AUTOSAR XML (schema 4-2-2)
package /STELLANTIS/EPT/ASWCs
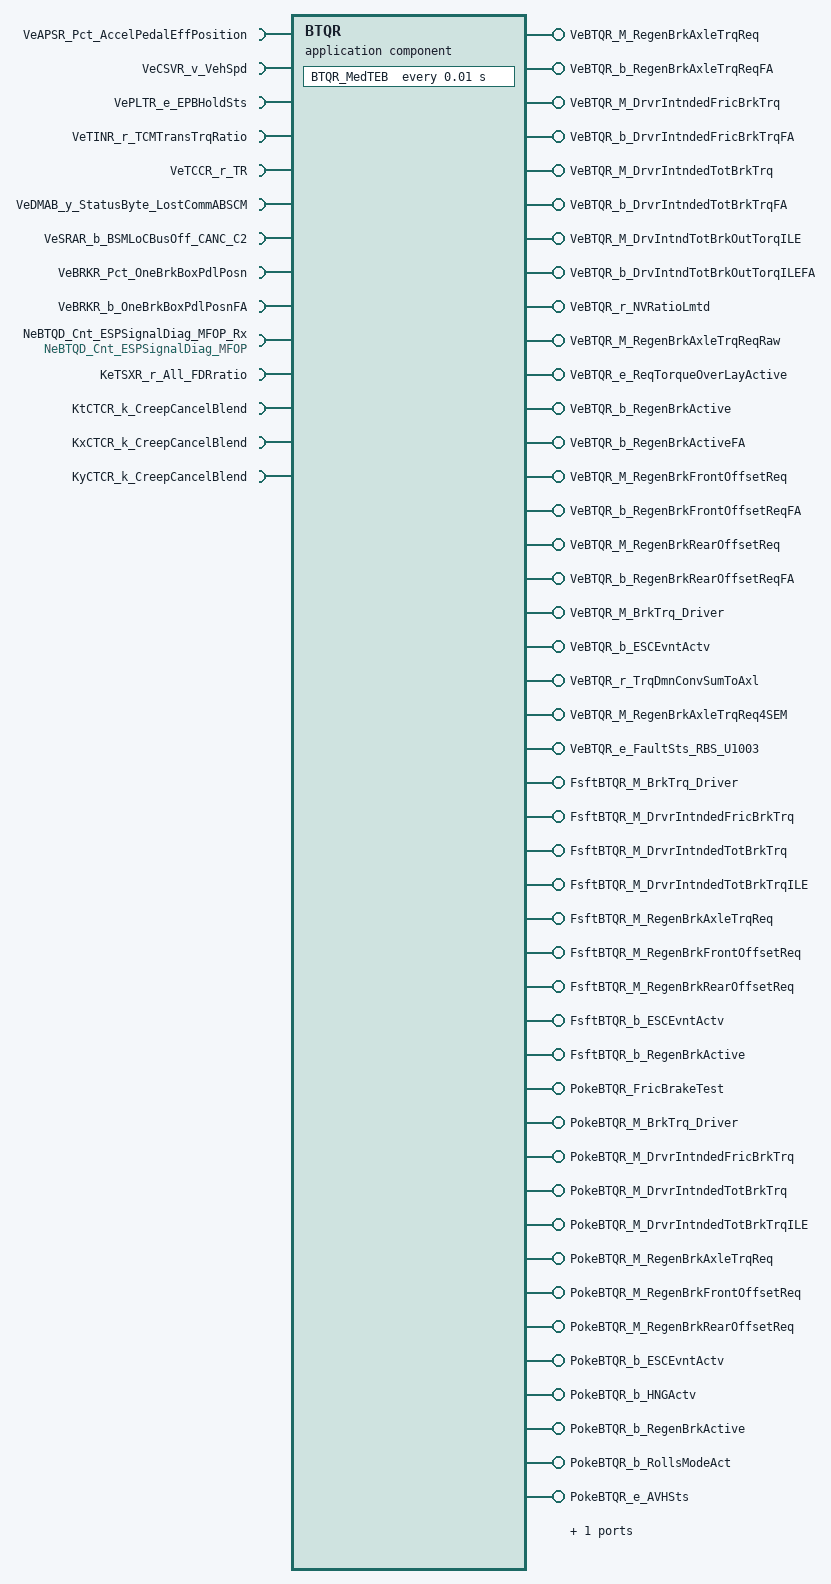
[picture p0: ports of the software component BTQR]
  application sw component type BTQR
    9 x require port:
      VeAPSR_Pct_AccelPedalEffPosition: variation-point={short-label=vpVeAPSR_Pct_AccelPedalEffPosition, sw-syscond=1}, nonqueued-receiver-com-spec{data-element=Value, init-value=0}, required-interface=VeAPSR_Pct_AccelPedalEffPosition
      VeCSVR_v_VehSpd: nonqueued-receiver-com-spec{data-element=Value, init-value=0}, required-interface=VeCSVR_v_VehSpd
      VePLTR_e_EPBHoldSts: variation-point={short-label=vpVePLTR_e_EPBHoldSts, sw-syscond=1}, nonqueued-receiver-com-spec{data-element=Value, init-value=CePLTR_e_EPBHoldSts_REL}, required-interface=VePLTR_e_EPBHoldSts
      VeTINR_r_TCMTransTrqRatio: variation-point={short-label=vpVeTINR_r_TCMTransTrqRatio, sw-syscond=1}, nonqueued-receiver-com-spec{data-element=Value, init-value=0}, required-interface=VeTINR_r_TCMTransTrqRatio
      VeTCCR_r_TR: variation-point={short-label=vpVeTCCR_r_TR, sw-syscond=1}, nonqueued-receiver-com-spec{data-element=Value, init-value=0}, required-interface=VeTCCR_r_TR
      VeDMAB_y_StatusByte_LostCommABSCM: nonqueued-receiver-com-spec{data-element=Value, init-value=0}, required-interface=VeDMAB_y_StatusByte_LostCommABSCM
      VeSRAR_b_BSMLoCBusOff_CANC_C2: variation-point={short-label=vpVeSRAR_b_BSMLoCBusOff_CANC_C2, sw-syscond=1}, nonqueued-receiver-com-spec{data-element=Value, init-value=0}, required-interface=VeSRAR_b_BSMLoCBusOff_CANC_C2
      VeBRKR_Pct_OneBrkBoxPdlPosn: variation-point={short-label=vpVeBRKR_Pct_OneBrkBoxPdlPosn, sw-syscond=1}, nonqueued-receiver-com-spec{data-element=Value, init-value=0}, required-interface=VeBRKR_Pct_OneBrkBoxPdlPosn
      VeBRKR_b_OneBrkBoxPdlPosnFA: variation-point={short-label=vpVeBRKR_b_OneBrkBoxPdlPosnFA, sw-syscond=1}, nonqueued-receiver-com-spec{data-element=Value, init-value=0}, required-interface=VeBRKR_b_OneBrkBoxPdlPosnFA
    44 x provide port:
      VeBTQR_M_RegenBrkAxleTrqReq: nonqueued-sender-com-spec{data-element=Value, init-value=0}, provided-interface=VeBTQR_M_RegenBrkAxleTrqReq
      VeBTQR_b_RegenBrkAxleTrqReqFA: nonqueued-sender-com-spec{data-element=Value, init-value=0}, provided-interface=VeBTQR_b_RegenBrkAxleTrqReqFA
      VeBTQR_M_DrvrIntndedFricBrkTrq: nonqueued-sender-com-spec{data-element=Value, init-value=0}, provided-interface=VeBTQR_M_DrvrIntndedFricBrkTrq
      VeBTQR_b_DrvrIntndedFricBrkTrqFA: nonqueued-sender-com-spec{data-element=Value, init-value=0}, provided-interface=VeBTQR_b_DrvrIntndedFricBrkTrqFA
      VeBTQR_M_DrvrIntndedTotBrkTrq: nonqueued-sender-com-spec{data-element=Value, init-value=0}, provided-interface=VeBTQR_M_DrvrIntndedTotBrkTrq
      VeBTQR_b_DrvrIntndedTotBrkTrqFA: nonqueued-sender-com-spec{data-element=Value, init-value=0}, provided-interface=VeBTQR_b_DrvrIntndedTotBrkTrqFA
      VeBTQR_M_DrvIntndTotBrkOutTorqILE: nonqueued-sender-com-spec{data-element=Value, init-value=0}, provided-interface=VeBTQR_M_DrvIntndTotBrkOutTorqILE
      VeBTQR_b_DrvIntndTotBrkOutTorqILEFA: nonqueued-sender-com-spec{data-element=Value, init-value=0}, provided-interface=VeBTQR_b_DrvIntndTotBrkOutTorqILEFA
      VeBTQR_r_NVRatioLmtd: nonqueued-sender-com-spec{data-element=Value, init-value=0}, provided-interface=VeBTQR_r_NVRatioLmtd
      VeBTQR_M_RegenBrkAxleTrqReqRaw: nonqueued-sender-com-spec{data-element=Value, init-value=0}, provided-interface=VeBTQR_M_RegenBrkAxleTrqReqRaw
      VeBTQR_e_ReqTorqueOverLayActive: nonqueued-sender-com-spec{data-element=Value, init-value=CeBTQR_e_NotApplied}, provided-interface=VeBTQR_e_ReqTorqueOverLayActive
      VeBTQR_b_RegenBrkActive: nonqueued-sender-com-spec{data-element=Value, init-value=0}, provided-interface=VeBTQR_b_RegenBrkActive
      VeBTQR_b_RegenBrkActiveFA: nonqueued-sender-com-spec{data-element=Value, init-value=0}, provided-interface=VeBTQR_b_RegenBrkActiveFA
      VeBTQR_M_RegenBrkFrontOffsetReq: nonqueued-sender-com-spec{data-element=Value, init-value=0}, provided-interface=VeBTQR_M_RegenBrkFrontOffsetReq
      VeBTQR_b_RegenBrkFrontOffsetReqFA: nonqueued-sender-com-spec{data-element=Value, init-value=0}, provided-interface=VeBTQR_b_RegenBrkFrontOffsetReqFA
      VeBTQR_M_RegenBrkRearOffsetReq: nonqueued-sender-com-spec{data-element=Value, init-value=0}, provided-interface=VeBTQR_M_RegenBrkRearOffsetReq
      VeBTQR_b_RegenBrkRearOffsetReqFA: nonqueued-sender-com-spec{data-element=Value, init-value=0}, provided-interface=VeBTQR_b_RegenBrkRearOffsetReqFA
      VeBTQR_M_BrkTrq_Driver: variation-point={short-label=vpVeBTQR_M_BrkTrq_Driver, sw-syscond=1}, nonqueued-sender-com-spec{data-element=Value, init-value=0}, provided-interface=VeBTQR_M_BrkTrq_Driver
      VeBTQR_b_ESCEvntActv: nonqueued-sender-com-spec{data-element=Value, init-value=0}, provided-interface=VeBTQR_b_ESCEvntActv
      VeBTQR_r_TrqDmnConvSumToAxl: nonqueued-sender-com-spec{data-element=Value, init-value=0}, provided-interface=VeBTQR_r_TrqDmnConvSumToAxl
      VeBTQR_M_RegenBrkAxleTrqReq4SEM: nonqueued-sender-com-spec{data-element=Value, init-value=0}, provided-interface=VeBTQR_M_RegenBrkAxleTrqReq4SEM
      VeBTQR_e_FaultSts_RBS_U1003: nonqueued-sender-com-spec{data-element=Value, init-value=CeDFIB_e_Init}, provided-interface=VeBTQR_e_FaultSts_RBS_U1003
      FsftBTQR_M_BrkTrq_Driver: server-com-spec=FsftBTQR_M_BrkTrq_Driver, provided-interface=FsftBTQR_M_BrkTrq_Driver
      FsftBTQR_M_DrvrIntndedFricBrkTrq: server-com-spec=FsftBTQR_M_DrvrIntndedFricBrkTrq, provided-interface=FsftBTQR_M_DrvrIntndedFricBrkTrq
      FsftBTQR_M_DrvrIntndedTotBrkTrq: server-com-spec=FsftBTQR_M_DrvrIntndedTotBrkTrq, provided-interface=FsftBTQR_M_DrvrIntndedTotBrkTrq
      FsftBTQR_M_DrvrIntndedTotBrkTrqILE: server-com-spec=FsftBTQR_M_DrvrIntndedTotBrkTrqILE, provided-interface=FsftBTQR_M_DrvrIntndedTotBrkTrqILE
      FsftBTQR_M_RegenBrkAxleTrqReq: server-com-spec=FsftBTQR_M_RegenBrkAxleTrqReq, provided-interface=FsftBTQR_M_RegenBrkAxleTrqReq
      FsftBTQR_M_RegenBrkFrontOffsetReq: server-com-spec=FsftBTQR_M_RegenBrkFrontOffsetReq, provided-interface=FsftBTQR_M_RegenBrkFrontOffsetReq
      FsftBTQR_M_RegenBrkRearOffsetReq: server-com-spec=FsftBTQR_M_RegenBrkRearOffsetReq, provided-interface=FsftBTQR_M_RegenBrkRearOffsetReq
      FsftBTQR_b_ESCEvntActv: server-com-spec=FsftBTQR_b_ESCEvntActv, provided-interface=FsftBTQR_b_ESCEvntActv
      FsftBTQR_b_RegenBrkActive: server-com-spec=FsftBTQR_b_RegenBrkActive, provided-interface=FsftBTQR_b_RegenBrkActive
      PokeBTQR_FricBrakeTest: server-com-spec{operation=PokeBTQR_FricBrakeTest, queue-length=1}, provided-interface=PokeBTQR_FricBrakeTest
      PokeBTQR_M_BrkTrq_Driver: server-com-spec{operation=PokeBTQR_M_BrkTrq_Driver, queue-length=1}, provided-interface=PokeBTQR_M_BrkTrq_Driver
      PokeBTQR_M_DrvrIntndedFricBrkTrq: server-com-spec{operation=PokeBTQR_M_DrvrIntndedFricBrkTrq, queue-length=1}, provided-interface=PokeBTQR_M_DrvrIntndedFricBrkTrq
      PokeBTQR_M_DrvrIntndedTotBrkTrq: server-com-spec{operation=PokeBTQR_M_DrvrIntndedTotBrkTrq, queue-length=1}, provided-interface=PokeBTQR_M_DrvrIntndedTotBrkTrq
      PokeBTQR_M_DrvrIntndedTotBrkTrqILE: server-com-spec{operation=PokeBTQR_M_DrvrIntndedTotBrkTrqILE, queue-length=1}, provided-interface=PokeBTQR_M_DrvrIntndedTotBrkTrqILE
      PokeBTQR_M_RegenBrkAxleTrqReq: server-com-spec{operation=PokeBTQR_M_RegenBrkAxleTrqReq, queue-length=1}, provided-interface=PokeBTQR_M_RegenBrkAxleTrqReq
      PokeBTQR_M_RegenBrkFrontOffsetReq: server-com-spec{operation=PokeBTQR_M_RegenBrkFrontOffsetReq, queue-length=1}, provided-interface=PokeBTQR_M_RegenBrkFrontOffsetReq
      PokeBTQR_M_RegenBrkRearOffsetReq: server-com-spec{operation=PokeBTQR_M_RegenBrkRearOffsetReq, queue-length=1}, provided-interface=PokeBTQR_M_RegenBrkRearOffsetReq
      PokeBTQR_b_ESCEvntActv: server-com-spec{operation=PokeBTQR_b_ESCEvntActv, queue-length=1}, provided-interface=PokeBTQR_b_ESCEvntActv
      PokeBTQR_b_HNGActv: server-com-spec{operation=PokeBTQR_b_HNGActv, queue-length=1}, provided-interface=PokeBTQR_b_HNGActv
      PokeBTQR_b_RegenBrkActive: server-com-spec{operation=PokeBTQR_b_RegenBrkActive, queue-length=1}, provided-interface=PokeBTQR_b_RegenBrkActive
      PokeBTQR_b_RollsModeAct: server-com-spec{operation=PokeBTQR_b_RollsModeAct, queue-length=1}, provided-interface=PokeBTQR_b_RollsModeAct
      PokeBTQR_e_AVHSts: server-com-spec{operation=PokeBTQR_e_AVHSts, queue-length=1}, provided-interface=PokeBTQR_e_AVHSts
    require port NeBTQD_Cnt_ESPSignalDiag_MFOP_Rx: nv-require-com-spec{init-value=0, variable=NeBTQD_Cnt_ESPSignalDiag_MFOP}, required-interface=NeBTQD_Cnt_ESPSignalDiag_MFOP
    provide port NeBTQD_Cnt_ESPSignalDiag_MFOP: nv-provide-com-spec{ram-block-init-value=0, variable=NeBTQD_Cnt_ESPSignalDiag_MFOP}, provided-interface=NeBTQD_Cnt_ESPSignalDiag_MFOP
    4 x require port:
      KeTSXR_r_All_FDRratio: parameter-require-com-spec{init-value=KeTSXR_r_All_FDRratio_KeTSXR_r_All_FDRratio:3.64023876190186, parameter=KeTSXR_r_All_FDRratio}, required-interface=KeTSXR_r_All_FDRratio
      KtCTCR_k_CreepCancelBlend: parameter-require-com-spec{init-value=[1 1 1 1 1 1 0.899999976158142 0.800000011920929 0.699999988079071 0.5 0.400000005960464 0.300000011920929 0.699999988079071 0.649999976158142 0.600000023841858 0.400000005960464 0.300000011920929 0.25 0.5 0.449999988079071 0.400000005960464 0.300000011920929 0.25 0.200000002980232 0.300000011920929 0.25 0.200000002980232 0.150000005960464 0.100000001490116 0.0500000007450581 0 0 0 0 0 0], parameter=KtCTCR_k_CreepCancelBlend}, required-interface=KtCTCR_k_CreepCancelBlend
      KxCTCR_k_CreepCancelBlend: parameter-require-com-spec{init-value=[0 2 5 7 10 20], parameter=KxCTCR_k_CreepCancelBlend}, required-interface=KxCTCR_k_CreepCancelBlend
      KyCTCR_k_CreepCancelBlend: parameter-require-com-spec{init-value=[0 200 500 1000 2000 2500], parameter=KyCTCR_k_CreepCancelBlend}, required-interface=KyCTCR_k_CreepCancelBlend
    behavior IB_BTQR: data-type-mapping=msADTtoIDTMapping, handle-termination-and-restart=NO-SUPPORT
      timing event Event_MedTEB: start-on-event=BTQR_MedTEB, period=0.01
      20 x operation invoked event:
        Event_FsftBTQR_M_BrkTrq_Driver: start-on-event=FsftBTQR_M_BrkTrq_Driver, operation=FsftBTQR_M_BrkTrq_Driver.FsftBTQR_M_BrkTrq_Driver
        Event_FsftBTQR_M_DrvrIntndedFricBrkTrq: start-on-event=FsftBTQR_M_DrvrIntndedFricBrkTrq, operation=FsftBTQR_M_DrvrIntndedFricBrkTrq.FsftBTQR_M_DrvrIntndedFricBrkTrq
        Event_FsftBTQR_M_DrvrIntndedTotBrkTrq: start-on-event=FsftBTQR_M_DrvrIntndedTotBrkTrq, operation=FsftBTQR_M_DrvrIntndedTotBrkTrq.FsftBTQR_M_DrvrIntndedTotBrkTrq
        Event_FsftBTQR_M_DrvrIntndedTotBrkTrqILE: start-on-event=FsftBTQR_M_DrvrIntndedTotBrkTrqILE, operation=FsftBTQR_M_DrvrIntndedTotBrkTrqILE.FsftBTQR_M_DrvrIntndedTotBrkTrqILE
        Event_FsftBTQR_M_RegenBrkAxleTrqReq: start-on-event=FsftBTQR_M_RegenBrkAxleTrqReq, operation=FsftBTQR_M_RegenBrkAxleTrqReq.FsftBTQR_M_RegenBrkAxleTrqReq
        Event_FsftBTQR_M_RegenBrkFrontOffsetReq: start-on-event=FsftBTQR_M_RegenBrkFrontOffsetReq, operation=FsftBTQR_M_RegenBrkFrontOffsetReq.FsftBTQR_M_RegenBrkFrontOffsetReq
        Event_FsftBTQR_M_RegenBrkRearOffsetReq: start-on-event=FsftBTQR_M_RegenBrkRearOffsetReq, operation=FsftBTQR_M_RegenBrkRearOffsetReq.FsftBTQR_M_RegenBrkRearOffsetReq
        Event_FsftBTQR_b_ESCEvntActv: start-on-event=FsftBTQR_b_ESCEvntActv, operation=FsftBTQR_b_ESCEvntActv.FsftBTQR_b_ESCEvntActv
        Event_FsftBTQR_b_RegenBrkActive: start-on-event=FsftBTQR_b_RegenBrkActive, operation=FsftBTQR_b_RegenBrkActive.FsftBTQR_b_RegenBrkActive
        Event_PokeBTQR_M_BrkTrq_Driver: start-on-event=PokeBTQR_M_BrkTrq_Driver, operation=PokeBTQR_M_BrkTrq_Driver.PokeBTQR_M_BrkTrq_Driver
        Event_PokeBTQR_M_DrvrIntndedFricBrkTrq: start-on-event=PokeBTQR_M_DrvrIntndedFricBrkTrq, operation=PokeBTQR_M_DrvrIntndedFricBrkTrq.PokeBTQR_M_DrvrIntndedFricBrkTrq
        Event_PokeBTQR_M_DrvrIntndedTotBrkTrq: start-on-event=PokeBTQR_M_DrvrIntndedTotBrkTrq, operation=PokeBTQR_M_DrvrIntndedTotBrkTrq.PokeBTQR_M_DrvrIntndedTotBrkTrq
        Event_PokeBTQR_M_DrvrIntndedTotBrkTrqILE: start-on-event=PokeBTQR_M_DrvrIntndedTotBrkTrqILE, operation=PokeBTQR_M_DrvrIntndedTotBrkTrqILE.PokeBTQR_M_DrvrIntndedTotBrkTrqILE
        Event_PokeBTQR_M_RegenBrkAxleTrqReq: start-on-event=PokeBTQR_M_RegenBrkAxleTrqReq, operation=PokeBTQR_M_RegenBrkAxleTrqReq.PokeBTQR_M_RegenBrkAxleTrqReq
        Event_PokeBTQR_M_RegenBrkFrontOffsetReq: start-on-event=PokeBTQR_M_RegenBrkFrontOffsetReq, operation=PokeBTQR_M_RegenBrkFrontOffsetReq.PokeBTQR_M_RegenBrkFrontOffsetReq
        Event_PokeBTQR_M_RegenBrkRearOffsetReq: start-on-event=PokeBTQR_M_RegenBrkRearOffsetReq, operation=PokeBTQR_M_RegenBrkRearOffsetReq.PokeBTQR_M_RegenBrkRearOffsetReq
        Event_PokeBTQR_b_ESCEvntActv: start-on-event=PokeBTQR_b_ESCEvntActv, operation=PokeBTQR_b_ESCEvntActv.PokeBTQR_b_ESCEvntActv
        Event_PokeBTQR_b_HNGActv: start-on-event=PokeBTQR_b_HNGActv, operation=PokeBTQR_b_HNGActv.PokeBTQR_b_HNGActv
        Event_PokeBTQR_b_RegenBrkActive: start-on-event=PokeBTQR_b_RegenBrkActive, operation=PokeBTQR_b_RegenBrkActive.PokeBTQR_b_RegenBrkActive
        Event_PokeBTQR_e_AVHSts: start-on-event=PokeBTQR_e_AVHSts, operation=PokeBTQR_e_AVHSts.PokeBTQR_e_AVHSts
      init event Event_BTQR_ac_Init: start-on-event=BTQR_ac_Init
      init event Event_PwrOn: start-on-event=BTQR_PwrOn
      init event Event_PwrOff: start-on-event=BTQR_PwrOff
      explicit-inter-runnable-variables:
        12 x data, all with category=VALUE, sw-calibration-access=READ-ONLY:
          DrvrIntndedFricBrkTrq_Init_write_IRV: type=Float, init-value=0, variation-point={short-label=vpDrvrIntndedFricBrkTrq_Init_write_IRV, sw-syscond=1}
          DrvrIntndedFricBrkTrqFA_Init_write_IRV: type=Boolean, init-value=0
          DrvrIntndedTotBrkTrq_Init_write_IRV: type=Float, init-value=0, variation-point={short-label=vpDrvrIntndedTotBrkTrq_Init_write_IRV, sw-syscond=1}
          DrvrIntndedTotBrkTrqFA_Init_write_IRV: type=Boolean, init-value=0
          DrvrIntndedTotBrkTrqILE_Init_write_IRV: type=Float, init-value=0, variation-point={short-label=vpDrvrIntndedTotBrkTrqILE_Init_write_IRV, sw-syscond=1}
          DrvrIntndedTotBrkTrqILEFA_Init_write_IRV: type=Boolean, init-value=0
          RegenBrkAxleTrqReq_Init_write_IRV: type=Float, init-value=0, variation-point={short-label=vpRegenBrkAxleTrqReq_Init_write_IRV, sw-syscond=1}
          RegenBrkAxleTrqReqFA_Init_write_IRV: type=Boolean, init-value=0
          AVHSts_Init_write_IRV: type=TeBTQR_e_AVHSts, init-value=CeBTQR_e_NotEnabled, variation-point={short-label=vpAVHSts_Init_write_IRV, sw-syscond=1}
          HNGActv_Init_write_IRV: type=Boolean, init-value=0, variation-point={short-label=vpHNGActv_Init_write_IRV, sw-syscond=1}
          ESCEvntActvFA_Init_write_IRV: type=Boolean, init-value=0
          ESCEvntActv_Init_write_IRV: type=Boolean, init-value=0
      24 x runnable:
        BTQR_ac_Init
          data-send-points:
            access OUT_VeBTQR_e_ReqTorqueOverLayActive_Value: accessed-variable=VeBTQR_e_ReqTorqueOverLayActive.Value
            access OUT_VeBTQR_e_FaultSts_RBS_U1003_Value: accessed-variable=VeBTQR_e_FaultSts_RBS_U1003.Value
        BTQR_PwrOn
          data-receive-point-by-arguments:
            access IN_NeBTQD_Cnt_ESPSignalDiag_MFOP_Rx_NeBTQD_Cnt_ESPSignalDiag_MFOP: accessed-variable=NeBTQD_Cnt_ESPSignalDiag_MFOP_Rx.NeBTQD_Cnt_ESPSignalDiag_MFOP
          data-send-points:
            22 x access:
              OUT_VeBTQR_b_RegenBrkAxleTrqReqFA_Value: accessed-variable=VeBTQR_b_RegenBrkAxleTrqReqFA.Value
              OUT_VeBTQR_b_RegenBrkFrontOffsetReqFA_Value: accessed-variable=VeBTQR_b_RegenBrkFrontOffsetReqFA.Value
              OUT_VeBTQR_M_RegenBrkFrontOffsetReq_Value: accessed-variable=VeBTQR_M_RegenBrkFrontOffsetReq.Value
              OUT_VeBTQR_b_RegenBrkRearOffsetReqFA_Value: accessed-variable=VeBTQR_b_RegenBrkRearOffsetReqFA.Value
              OUT_VeBTQR_M_RegenBrkRearOffsetReq_Value: accessed-variable=VeBTQR_M_RegenBrkRearOffsetReq.Value
              OUT_VeBTQR_M_BrkTrq_Driver_Value: accessed-variable=VeBTQR_M_BrkTrq_Driver.Value, variation-point={short-label=vpOUT_VeBTQR_M_BrkTrq_Driver_Value, sw-syscond=1}
              OUT_VeBTQR_b_ESCEvntActv_Value: accessed-variable=VeBTQR_b_ESCEvntActv.Value
              OUT_VeBTQR_b_DrvrIntndedTotBrkTrqFA_Value: accessed-variable=VeBTQR_b_DrvrIntndedTotBrkTrqFA.Value
              OUT_VeBTQR_b_DrvrIntndedFricBrkTrqFA_Value: accessed-variable=VeBTQR_b_DrvrIntndedFricBrkTrqFA.Value
              OUT_VeBTQR_b_DrvIntndTotBrkOutTorqILEFA_Value: accessed-variable=VeBTQR_b_DrvIntndTotBrkOutTorqILEFA.Value
              OUT_VeBTQR_b_RegenBrkActiveFA_Value: accessed-variable=VeBTQR_b_RegenBrkActiveFA.Value
              OUT_VeBTQR_b_RegenBrkActive_Value: accessed-variable=VeBTQR_b_RegenBrkActive.Value
              OUT_VeBTQR_e_ReqTorqueOverLayActive_Value: accessed-variable=VeBTQR_e_ReqTorqueOverLayActive.Value
              OUT_VeBTQR_r_TrqDmnConvSumToAxl_Value: accessed-variable=VeBTQR_r_TrqDmnConvSumToAxl.Value
              OUT_VeBTQR_M_DrvrIntndedFricBrkTrq_Value: accessed-variable=VeBTQR_M_DrvrIntndedFricBrkTrq.Value
              OUT_VeBTQR_M_DrvIntndTotBrkOutTorqILE_Value: accessed-variable=VeBTQR_M_DrvIntndTotBrkOutTorqILE.Value
              OUT_VeBTQR_M_RegenBrkAxleTrqReq_Value: accessed-variable=VeBTQR_M_RegenBrkAxleTrqReq.Value
              OUT_VeBTQR_M_DrvrIntndedTotBrkTrq_Value: accessed-variable=VeBTQR_M_DrvrIntndedTotBrkTrq.Value
              OUT_VeBTQR_M_RegenBrkAxleTrqReqRaw_Value: accessed-variable=VeBTQR_M_RegenBrkAxleTrqReqRaw.Value
              OUT_VeBTQR_r_NVRatioLmtd_Value: accessed-variable=VeBTQR_r_NVRatioLmtd.Value
              OUT_VeBTQR_M_RegenBrkAxleTrqReq4SEM_Value: accessed-variable=VeBTQR_M_RegenBrkAxleTrqReq4SEM.Value
              OUT_VeBTQR_e_FaultSts_RBS_U1003_Value: accessed-variable=VeBTQR_e_FaultSts_RBS_U1003.Value
          written-local-variables:
            12 x access:
              WV_AVHSts_Init_write_IRV: accessed-variable=AVHSts_Init_write_IRV, variation-point={short-label=vpWV_AVHSts_Init_write_IRV, sw-syscond=1}
              WV_DrvrIntndedFricBrkTrqFA_Init_write_IRV: accessed-variable=DrvrIntndedFricBrkTrqFA_Init_write_IRV
              WV_DrvrIntndedFricBrkTrq_Init_write_IRV: accessed-variable=DrvrIntndedFricBrkTrq_Init_write_IRV, variation-point={short-label=vpWV_DrvrIntndedFricBrkTrq_Init_write_IRV, sw-syscond=1}
              WV_DrvrIntndedTotBrkTrqFA_Init_write_IRV: accessed-variable=DrvrIntndedTotBrkTrqFA_Init_write_IRV
              WV_DrvrIntndedTotBrkTrqILEFA_Init_write_IRV: accessed-variable=DrvrIntndedTotBrkTrqILEFA_Init_write_IRV
              WV_DrvrIntndedTotBrkTrqILE_Init_write_IRV: accessed-variable=DrvrIntndedTotBrkTrqILE_Init_write_IRV, variation-point={short-label=vpWV_DrvrIntndedTotBrkTrqILE_Init_write_IRV, sw-syscond=1}
              WV_DrvrIntndedTotBrkTrq_Init_write_IRV: accessed-variable=DrvrIntndedTotBrkTrq_Init_write_IRV, variation-point={short-label=vpWV_DrvrIntndedTotBrkTrq_Init_write_IRV, sw-syscond=1}
              WV_ESCEvntActvFA_Init_write_IRV: accessed-variable=ESCEvntActvFA_Init_write_IRV
              WV_ESCEvntActv_Init_write_IRV: accessed-variable=ESCEvntActv_Init_write_IRV
              WV_HNGActv_Init_write_IRV: accessed-variable=HNGActv_Init_write_IRV, variation-point={short-label=vpWV_HNGActv_Init_write_IRV, sw-syscond=1}
              WV_RegenBrkAxleTrqReqFA_Init_write_IRV: accessed-variable=RegenBrkAxleTrqReqFA_Init_write_IRV
              WV_RegenBrkAxleTrqReq_Init_write_IRV: accessed-variable=RegenBrkAxleTrqReq_Init_write_IRV, variation-point={short-label=vpWV_RegenBrkAxleTrqReq_Init_write_IRV, sw-syscond=1}
        BTQR_PwrOff
          data-send-points:
            access OUT_NeBTQD_Cnt_ESPSignalDiag_MFOP_NeBTQD_Cnt_ESPSignalDiag_MFOP: accessed-variable=NeBTQD_Cnt_ESPSignalDiag_MFOP.NeBTQD_Cnt_ESPSignalDiag_MFOP
        BTQR_MedTEB
          data-receive-point-by-arguments:
            9 x access:
              IN_VeAPSR_Pct_AccelPedalEffPosition_Value: accessed-variable=VeAPSR_Pct_AccelPedalEffPosition.Value, variation-point={short-label=vpIN_VeAPSR_Pct_AccelPedalEffPosition_Value, sw-syscond=1}
              IN_VeBRKR_Pct_OneBrkBoxPdlPosn_Value: accessed-variable=VeBRKR_Pct_OneBrkBoxPdlPosn.Value, variation-point={short-label=vpIN_VeBRKR_Pct_OneBrkBoxPdlPosn_Value, sw-syscond=1}
              IN_VeBRKR_b_OneBrkBoxPdlPosnFA_Value: accessed-variable=VeBRKR_b_OneBrkBoxPdlPosnFA.Value, variation-point={short-label=vpIN_VeBRKR_b_OneBrkBoxPdlPosnFA_Value, sw-syscond=1}
              IN_VeCSVR_v_VehSpd_Value: accessed-variable=VeCSVR_v_VehSpd.Value
              IN_VeDMAB_y_StatusByte_LostCommABSCM_Value: accessed-variable=VeDMAB_y_StatusByte_LostCommABSCM.Value
              IN_VePLTR_e_EPBHoldSts_Value: accessed-variable=VePLTR_e_EPBHoldSts.Value, variation-point={short-label=vpIN_VePLTR_e_EPBHoldSts_Value, sw-syscond=1}
              IN_VeSRAR_b_BSMLoCBusOff_CANC_C2_Value: accessed-variable=VeSRAR_b_BSMLoCBusOff_CANC_C2.Value, variation-point={short-label=vpIN_VeSRAR_b_BSMLoCBusOff_CANC_C2_Value, sw-syscond=1}
              IN_VeTCCR_r_TR_Value: accessed-variable=VeTCCR_r_TR.Value, variation-point={short-label=vpIN_VeTCCR_r_TR_Value, sw-syscond=1}
              IN_VeTINR_r_TCMTransTrqRatio_Value: accessed-variable=VeTINR_r_TCMTransTrqRatio.Value, variation-point={short-label=vpIN_VeTINR_r_TCMTransTrqRatio_Value, sw-syscond=1}
          data-send-points:
            10 x access:
              OUT_VeBTQR_M_DrvrIntndedTotBrkTrq_Value: accessed-variable=VeBTQR_M_DrvrIntndedTotBrkTrq.Value
              OUT_VeBTQR_M_DrvIntndTotBrkOutTorqILE_Value: accessed-variable=VeBTQR_M_DrvIntndTotBrkOutTorqILE.Value
              OUT_VeBTQR_M_RegenBrkAxleTrqReq_Value: accessed-variable=VeBTQR_M_RegenBrkAxleTrqReq.Value
              OUT_VeBTQR_r_NVRatioLmtd_Value: accessed-variable=VeBTQR_r_NVRatioLmtd.Value
              OUT_VeBTQR_r_TrqDmnConvSumToAxl_Value: accessed-variable=VeBTQR_r_TrqDmnConvSumToAxl.Value
              OUT_VeBTQR_M_DrvrIntndedFricBrkTrq_Value: accessed-variable=VeBTQR_M_DrvrIntndedFricBrkTrq.Value
              OUT_VeBTQR_e_ReqTorqueOverLayActive_Value: accessed-variable=VeBTQR_e_ReqTorqueOverLayActive.Value
              OUT_VeBTQR_M_RegenBrkAxleTrqReqRaw_Value: accessed-variable=VeBTQR_M_RegenBrkAxleTrqReqRaw.Value
              OUT_VeBTQR_M_RegenBrkAxleTrqReq4SEM_Value: accessed-variable=VeBTQR_M_RegenBrkAxleTrqReq4SEM.Value
              OUT_VeBTQR_e_FaultSts_RBS_U1003_Value: accessed-variable=VeBTQR_e_FaultSts_RBS_U1003.Value
          4 x parameter access:
            CALPRM_KeTSXR_r_All_FDRratio_KeTSXR_r_All_FDRratio: accessed-parameter=KeTSXR_r_All_FDRratio.KeTSXR_r_All_FDRratio, variation-point={short-label=vpCALPRM_KeTSXR_r_All_FDRratio_KeTSXR_r_All_FDRratio, sw-syscond=1}
            CALPRM_KtCTCR_k_CreepCancelBlend_KtCTCR_k_CreepCancelBlend: accessed-parameter=KtCTCR_k_CreepCancelBlend.KtCTCR_k_CreepCancelBlend, variation-point={short-label=vpCALPRM_KtCTCR_k_CreepCancelBlend_KtCTCR_k_CreepCancelBlend, sw-syscond=1}
            CALPRM_KxCTCR_k_CreepCancelBlend_KxCTCR_k_CreepCancelBlend: accessed-parameter=KxCTCR_k_CreepCancelBlend.KxCTCR_k_CreepCancelBlend, variation-point={short-label=vpCALPRM_KxCTCR_k_CreepCancelBlend_KxCTCR_k_CreepCancelBlend, sw-syscond=1}
            CALPRM_KyCTCR_k_CreepCancelBlend_KyCTCR_k_CreepCancelBlend: accessed-parameter=KyCTCR_k_CreepCancelBlend.KyCTCR_k_CreepCancelBlend, variation-point={short-label=vpCALPRM_KyCTCR_k_CreepCancelBlend_KyCTCR_k_CreepCancelBlend, sw-syscond=1}
          read-local-variables:
            11 x access:
              RV_AVHSts_Init_write_IRV: accessed-variable=AVHSts_Init_write_IRV, variation-point={short-label=vpRV_AVHSts_Init_write_IRV, sw-syscond=1}
              RV_DrvrIntndedFricBrkTrqFA_Init_write_IRV: accessed-variable=DrvrIntndedFricBrkTrqFA_Init_write_IRV, variation-point={short-label=vpRV_DrvrIntndedFricBrkTrqFA_Init_write_IRV, sw-syscond=1}
              RV_DrvrIntndedFricBrkTrq_Init_write_IRV: accessed-variable=DrvrIntndedFricBrkTrq_Init_write_IRV, variation-point={short-label=vpRV_DrvrIntndedFricBrkTrq_Init_write_IRV, sw-syscond=1}
              RV_DrvrIntndedTotBrkTrqFA_Init_write_IRV: accessed-variable=DrvrIntndedTotBrkTrqFA_Init_write_IRV, variation-point={short-label=vpRV_DrvrIntndedTotBrkTrqFA_Init_write_IRV, sw-syscond=1}
              RV_DrvrIntndedTotBrkTrqILEFA_Init_write_IRV: accessed-variable=DrvrIntndedTotBrkTrqILEFA_Init_write_IRV, variation-point={short-label=vpRV_DrvrIntndedTotBrkTrqILEFA_Init_write_IRV, sw-syscond=1}
              RV_DrvrIntndedTotBrkTrqILE_Init_write_IRV: accessed-variable=DrvrIntndedTotBrkTrqILE_Init_write_IRV, variation-point={short-label=vpRV_DrvrIntndedTotBrkTrqILE_Init_write_IRV, sw-syscond=1}
              RV_DrvrIntndedTotBrkTrq_Init_write_IRV: accessed-variable=DrvrIntndedTotBrkTrq_Init_write_IRV, variation-point={short-label=vpRV_DrvrIntndedTotBrkTrq_Init_write_IRV, sw-syscond=1}
              RV_ESCEvntActvFA_Init_write_IRV: accessed-variable=ESCEvntActvFA_Init_write_IRV
              RV_HNGActv_Init_write_IRV: accessed-variable=HNGActv_Init_write_IRV, variation-point={short-label=vpRV_HNGActv_Init_write_IRV, sw-syscond=1}
              RV_RegenBrkAxleTrqReqFA_Init_write_IRV: accessed-variable=RegenBrkAxleTrqReqFA_Init_write_IRV, variation-point={short-label=vpRV_RegenBrkAxleTrqReqFA_Init_write_IRV, sw-syscond=1}
              RV_RegenBrkAxleTrqReq_Init_write_IRV: accessed-variable=RegenBrkAxleTrqReq_Init_write_IRV, variation-point={short-label=vpRV_RegenBrkAxleTrqReq_Init_write_IRV, sw-syscond=1}
        FsftBTQR_M_BrkTrq_Driver: variation-point={short-label=vpFsftBTQR_M_BrkTrq_Driver, sw-syscond=1}
        FsftBTQR_M_DrvrIntndedFricBrkTrq: variation-point={short-label=vpFsftBTQR_M_DrvrIntndedFricBrkTrq, sw-syscond=1}
          data-send-points:
            access OUT_VeBTQR_b_DrvrIntndedFricBrkTrqFA_Value: accessed-variable=VeBTQR_b_DrvrIntndedFricBrkTrqFA.Value
          written-local-variables:
            access WV_DrvrIntndedFricBrkTrqFA_Init_write_IRV: accessed-variable=DrvrIntndedFricBrkTrqFA_Init_write_IRV, variation-point={short-label=vpWV_DrvrIntndedFricBrkTrqFA_Init_write_IRV, sw-syscond=1}
        FsftBTQR_M_DrvrIntndedTotBrkTrq: variation-point={short-label=vpFsftBTQR_M_DrvrIntndedTotBrkTrq, sw-syscond=1}
          data-send-points:
            access OUT_VeBTQR_b_DrvrIntndedTotBrkTrqFA_Value: accessed-variable=VeBTQR_b_DrvrIntndedTotBrkTrqFA.Value
          written-local-variables:
            access WV_DrvrIntndedTotBrkTrqFA_Init_write_IRV: accessed-variable=DrvrIntndedTotBrkTrqFA_Init_write_IRV, variation-point={short-label=vpWV_DrvrIntndedTotBrkTrqFA_Init_write_IRV, sw-syscond=1}
        FsftBTQR_M_DrvrIntndedTotBrkTrqILE: variation-point={short-label=vpFsftBTQR_M_DrvrIntndedTotBrkTrqILE, sw-syscond=1}
          data-send-points:
            access OUT_VeBTQR_b_DrvIntndTotBrkOutTorqILEFA_Value: accessed-variable=VeBTQR_b_DrvIntndTotBrkOutTorqILEFA.Value
          written-local-variables:
            access WV_DrvrIntndedTotBrkTrqILEFA_Init_write_IRV: accessed-variable=DrvrIntndedTotBrkTrqILEFA_Init_write_IRV, variation-point={short-label=vpWV_DrvrIntndedTotBrkTrqILEFA_Init_write_IRV, sw-syscond=1}
        FsftBTQR_M_RegenBrkAxleTrqReq: variation-point={short-label=vpFsftBTQR_M_RegenBrkAxleTrqReq, sw-syscond=1}
          data-send-points:
            access OUT_VeBTQR_b_RegenBrkAxleTrqReqFA_Value: accessed-variable=VeBTQR_b_RegenBrkAxleTrqReqFA.Value
          written-local-variables:
            access WV_RegenBrkAxleTrqReqFA_Init_write_IRV: accessed-variable=RegenBrkAxleTrqReqFA_Init_write_IRV, variation-point={short-label=vpWV_RegenBrkAxleTrqReqFA_Init_write_IRV, sw-syscond=1}
        FsftBTQR_M_RegenBrkFrontOffsetReq: variation-point={short-label=vpFsftBTQR_M_RegenBrkFrontOffsetReq, sw-syscond=1}
          data-send-points:
            access OUT_VeBTQR_b_RegenBrkFrontOffsetReqFA_Value: accessed-variable=VeBTQR_b_RegenBrkFrontOffsetReqFA.Value
        FsftBTQR_M_RegenBrkRearOffsetReq: variation-point={short-label=vpFsftBTQR_M_RegenBrkRearOffsetReq, sw-syscond=1}
          data-send-points:
            access OUT_VeBTQR_b_RegenBrkRearOffsetReqFA_Value: accessed-variable=VeBTQR_b_RegenBrkRearOffsetReqFA.Value
        FsftBTQR_b_ESCEvntActv
          data-send-points:
            access OUT_VeBTQR_b_ESCEvntActv_Value: accessed-variable=VeBTQR_b_ESCEvntActv.Value
          written-local-variables:
            access WV_ESCEvntActvFA_Init_write_IRV: accessed-variable=ESCEvntActvFA_Init_write_IRV
        FsftBTQR_b_RegenBrkActive: variation-point={short-label=vpFsftBTQR_b_RegenBrkActive, sw-syscond=1}
          data-send-points:
            access OUT_VeBTQR_b_RegenBrkActiveFA_Value: accessed-variable=VeBTQR_b_RegenBrkActiveFA.Value
        PokeBTQR_M_BrkTrq_Driver: variation-point={short-label=vpPokeBTQR_M_BrkTrq_Driver, sw-syscond=1}
          data-send-points:
            access OUT_VeBTQR_M_BrkTrq_Driver_Value: accessed-variable=VeBTQR_M_BrkTrq_Driver.Value, variation-point={short-label=vpOUT_VeBTQR_M_BrkTrq_Driver_Value, sw-syscond=1}
        PokeBTQR_M_DrvrIntndedFricBrkTrq: variation-point={short-label=vpPokeBTQR_M_DrvrIntndedFricBrkTrq, sw-syscond=1}
          data-send-points:
            access OUT_VeBTQR_b_DrvrIntndedFricBrkTrqFA_Value: accessed-variable=VeBTQR_b_DrvrIntndedFricBrkTrqFA.Value
          written-local-variables:
            access WV_DrvrIntndedFricBrkTrq_Init_write_IRV: accessed-variable=DrvrIntndedFricBrkTrq_Init_write_IRV, variation-point={short-label=vpWV_DrvrIntndedFricBrkTrq_Init_write_IRV, sw-syscond=1}
            access WV_DrvrIntndedFricBrkTrqFA_Init_write_IRV: accessed-variable=DrvrIntndedFricBrkTrqFA_Init_write_IRV, variation-point={short-label=vpWV_DrvrIntndedFricBrkTrqFA_Init_write_IRV, sw-syscond=1}
        PokeBTQR_M_DrvrIntndedTotBrkTrq: variation-point={short-label=vpPokeBTQR_M_DrvrIntndedTotBrkTrq, sw-syscond=1}
          data-send-points:
            access OUT_VeBTQR_b_DrvrIntndedTotBrkTrqFA_Value: accessed-variable=VeBTQR_b_DrvrIntndedTotBrkTrqFA.Value
          written-local-variables:
            access WV_DrvrIntndedTotBrkTrq_Init_write_IRV: accessed-variable=DrvrIntndedTotBrkTrq_Init_write_IRV, variation-point={short-label=vpWV_DrvrIntndedTotBrkTrq_Init_write_IRV, sw-syscond=1}
            access WV_DrvrIntndedTotBrkTrqFA_Init_write_IRV: accessed-variable=DrvrIntndedTotBrkTrqFA_Init_write_IRV, variation-point={short-label=vpWV_DrvrIntndedTotBrkTrqFA_Init_write_IRV, sw-syscond=1}
        PokeBTQR_M_DrvrIntndedTotBrkTrqILE: variation-point={short-label=vpPokeBTQR_M_DrvrIntndedTotBrkTrqILE, sw-syscond=1}
          data-send-points:
            access OUT_VeBTQR_b_DrvIntndTotBrkOutTorqILEFA_Value: accessed-variable=VeBTQR_b_DrvIntndTotBrkOutTorqILEFA.Value
          written-local-variables:
            access WV_DrvrIntndedTotBrkTrqILE_Init_write_IRV: accessed-variable=DrvrIntndedTotBrkTrqILE_Init_write_IRV, variation-point={short-label=vpWV_DrvrIntndedTotBrkTrqILE_Init_write_IRV, sw-syscond=1}
            access WV_DrvrIntndedTotBrkTrqILEFA_Init_write_IRV: accessed-variable=DrvrIntndedTotBrkTrqILEFA_Init_write_IRV, variation-point={short-label=vpWV_DrvrIntndedTotBrkTrqILEFA_Init_write_IRV, sw-syscond=1}
        PokeBTQR_M_RegenBrkAxleTrqReq: variation-point={short-label=vpPokeBTQR_M_RegenBrkAxleTrqReq, sw-syscond=1}
          data-send-points:
            access OUT_VeBTQR_b_RegenBrkAxleTrqReqFA_Value: accessed-variable=VeBTQR_b_RegenBrkAxleTrqReqFA.Value
          written-local-variables:
            access WV_RegenBrkAxleTrqReq_Init_write_IRV: accessed-variable=RegenBrkAxleTrqReq_Init_write_IRV, variation-point={short-label=vpWV_RegenBrkAxleTrqReq_Init_write_IRV, sw-syscond=1}
            access WV_RegenBrkAxleTrqReqFA_Init_write_IRV: accessed-variable=RegenBrkAxleTrqReqFA_Init_write_IRV, variation-point={short-label=vpWV_RegenBrkAxleTrqReqFA_Init_write_IRV, sw-syscond=1}
        PokeBTQR_M_RegenBrkFrontOffsetReq: variation-point={short-label=vpPokeBTQR_M_RegenBrkFrontOffsetReq, sw-syscond=1}
          data-send-points:
            access OUT_VeBTQR_M_RegenBrkFrontOffsetReq_Value: accessed-variable=VeBTQR_M_RegenBrkFrontOffsetReq.Value
            access OUT_VeBTQR_b_RegenBrkFrontOffsetReqFA_Value: accessed-variable=VeBTQR_b_RegenBrkFrontOffsetReqFA.Value
        PokeBTQR_M_RegenBrkRearOffsetReq: variation-point={short-label=vpPokeBTQR_M_RegenBrkRearOffsetReq, sw-syscond=1}
          data-send-points:
            access OUT_VeBTQR_M_RegenBrkRearOffsetReq_Value: accessed-variable=VeBTQR_M_RegenBrkRearOffsetReq.Value
            access OUT_VeBTQR_b_RegenBrkRearOffsetReqFA_Value: accessed-variable=VeBTQR_b_RegenBrkRearOffsetReqFA.Value
        PokeBTQR_b_ESCEvntActv
          data-send-points:
            access OUT_VeBTQR_b_ESCEvntActv_Value: accessed-variable=VeBTQR_b_ESCEvntActv.Value
          written-local-variables:
            access WV_ESCEvntActvFA_Init_write_IRV: accessed-variable=ESCEvntActvFA_Init_write_IRV
        PokeBTQR_b_HNGActv: variation-point={short-label=vpPokeBTQR_b_HNGActv, sw-syscond=1}
          written-local-variables:
            access WV_HNGActv_Init_write_IRV: accessed-variable=HNGActv_Init_write_IRV, variation-point={short-label=vpWV_HNGActv_Init_write_IRV, sw-syscond=1}
        PokeBTQR_b_RegenBrkActive: variation-point={short-label=vpPokeBTQR_b_RegenBrkActive, sw-syscond=1}
          data-send-points:
            access OUT_VeBTQR_b_RegenBrkActive_Value: accessed-variable=VeBTQR_b_RegenBrkActive.Value
            access OUT_VeBTQR_b_RegenBrkActiveFA_Value: accessed-variable=VeBTQR_b_RegenBrkActiveFA.Value
        PokeBTQR_e_AVHSts: variation-point={short-label=vpPokeBTQR_e_AVHSts, sw-syscond=1}
          written-local-variables:
            access WV_AVHSts_Init_write_IRV: accessed-variable=AVHSts_Init_write_IRV, variation-point={short-label=vpWV_AVHSts_Init_write_IRV, sw-syscond=1}
      variation point proxy Variant_BTQR_1: category=CONDITION, condition-access=0
      variation point proxy Variant_BTQR_2: category=CONDITION, condition-access=1
